# APM32L07x register map
File version: 1.0
CPU: CM0+ r0p0, little endian, MPU, no FPU, 4 interrupt priority bits
Registers are 32-bit, read-write, reset 0x0 unless marked. A register's access mark holds for its fields unless they carry their own. Offsets are from the block's base; [hi:lo] are bit positions.

## USART1 — Universal synchronous asynchronous receiver transmitter
Base 0x40013800
Same registers: USART2 0x40004400, USART4 0x40004C00, USART5 0x40005000
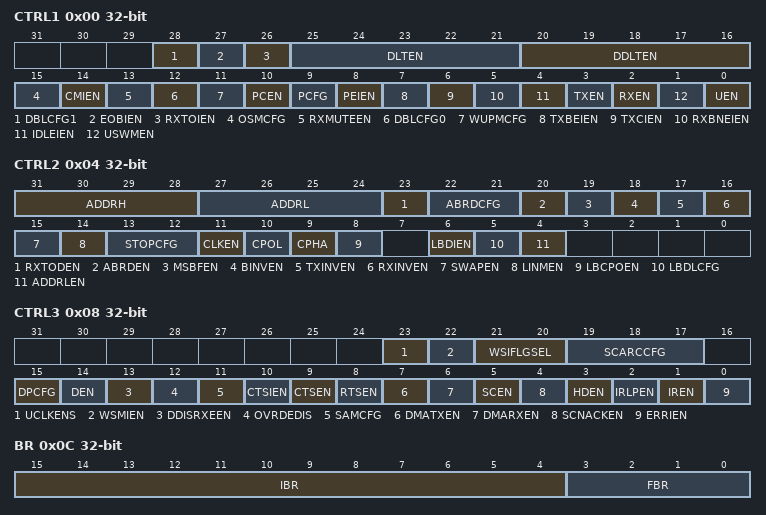
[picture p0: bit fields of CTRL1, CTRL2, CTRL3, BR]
0x00 CTRL1 — Control register 1
  [28] DBLCFG1 — Word length
  [27] EOBIEN — End of Block interrupt enable
  [26] RXTOIEN — Receiver timeout interrupt enable
  [25:21] DLTEN — Driver Enable assertion time
  [20:16] DDLTEN — Driver Enable deassertion time
  [15] OSMCFG — Oversampling mode
  [14] CMIEN — Character match interrupt enable
  [13] RXMUTEEN — Mute mode enable
  [12] DBLCFG0 — Word length
  [11] WUPMCFG — Receiver wakeup method
  [10] PCEN — Parity control enable
  [9] PCFG — Parity selection
  [8] PEIEN — PE interrupt enable
  [7] TXBEIEN — interrupt enable
  [6] TXCIEN — Transmission complete interrupt enable
  [5] RXBNEIEN — RXNE interrupt enable
  [4] IDLEIEN — IDLE interrupt enable
  [3] TXEN — Transmitter enable
  [2] RXEN — Receiver enable
  [1] USWMEN — USART enable in Stop mode
  [0] UEN — USART enable
0x04 CTRL2 — Control register 2
  [31:28] ADDRH — Address of the USART node
  [27:24] ADDRL — Address of the USART node
  [23] RXTODEN — Receiver timeout enable
  [22:21] ABRDCFG — Auto baud rate mode
  [20] ABRDEN — Auto baud rate enable
  [19] MSBFEN — Most significant bit first
  [18] BINVEN — Binary data inversion
  [17] TXINVEN — TX pin active level inversion
  [16] RXINVEN — RX pin active level inversion
  [15] SWAPEN — Swap TX/RX pins
  [14] LINMEN — LIN mode enable
  [13:12] STOPCFG — STOP bits
  [11] CLKEN — Clock enable
  [10] CPOL — Clock polarity
  [9] CPHA — Clock phase
  [8] LBCPOEN — Last bit clock pulse
  [6] LBDIEN — LIN break detection interrupt enable
  [5] LBDLCFG — LIN break detection length
  [4] ADDRLEN — 7-bit Address Detection/4-bit Address Detection
0x08 CTRL3 — Control register 3
  [23] UCLKENS — USART Clock Enable in Stop Mode
  [22] WSMIEN — Wakeup from Stop mode interrupt enable
  [21:20] WSIFLGSEL — Wakeup from Stop mode interrupt flag selection
  [19:17] SCARCCFG — Smartcard auto-retry count
  [15] DPCFG — Driver enable polarity selection
  [14] DEN — Driver enable mode
  [13] DDISRXEEN — DMA Disable on Reception Error
  [12] OVRDEDIS — Overrun Disable
  [11] SAMCFG — One sample bit method enable
  [10] CTSIEN — CTS interrupt enable
  [9] CTSEN — CTS enable
  [8] RTSEN — RTS enable
  [7] DMATXEN — DMA enable transmitter
  [6] DMARXEN — DMA enable receiver
  [5] SCEN — Smartcard mode enable
  [4] SCNACKEN — Smartcard NACK enable
  [3] HDEN — Half-duplex selection
  [2] IRLPEN — IrDA low-power
  [1] IREN — IrDA mode enable
  [0] ERRIEN — Error interrupt enable
0x0C BR — Baud rate register
  [15:4] IBR — mantissa of USARTDIV
  [3:0] FBR — fraction of USARTDIV
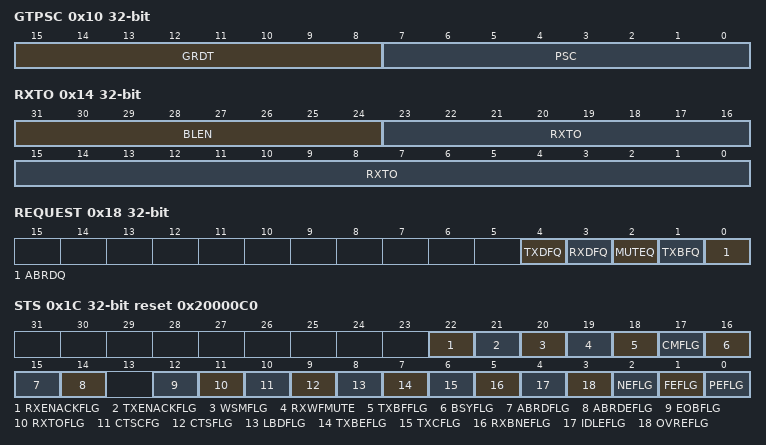
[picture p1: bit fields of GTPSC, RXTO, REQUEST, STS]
0x10 GTPSC — Guard time and prescaler register
  [15:8] GRDT — Guard time value
  [7:0] PSC — Prescaler value
0x14 RXTO — Receiver timeout register
  [31:24] BLEN — Block Length
  [23:0] RXTO — Receiver timeout value
0x18 REQUEST wo
  [4] TXDFQ — Transmit data flush request
  [3] RXDFQ — Receive data flush request
  [2] MUTEQ — Mute mode request
  [1] TXBFQ — Send break request
  [0] ABRDQ — Auto baud rate request
0x1C STS ro reset 0x20000C0 — Interrupt & status register
  [22] RXENACKFLG — Receive enable acknowledge flag
  [21] TXENACKFLG — Transmit enable acknowledge flag
  [20] WSMFLG — Wakeup from Stop mode flag
  [19] RXWFMUTE — Receiver wakeup from Mute mode
  [18] TXBFFLG — Send break flag
  [17] CMFLG — character match flag
  [16] BSYFLG — Busy flag
  [15] ABRDFLG — Auto baud rate flag
  [14] ABRDEFLG — Auto baud rate error
  [12] EOBFLG — End of block flag
  [11] RXTOFLG — Receiver timeout
  [10] CTSCFG — CTS flag
  [9] CTSFLG — CTS interrupt flag
  [8] LBDFLG — LIN break detection flag
  [7] TXBEFLG — Transmit data register empty
  [6] TXCFLG — Transmission complete
  [5] RXBNEFLG — Read data register not empty
  [4] IDLEFLG — Idle line detected
  [3] OVREFLG — Overrun error
  [2] NEFLG — Noise detected flag
  [1] FEFLG — Framing error
  [0] PEFLG — Parity error
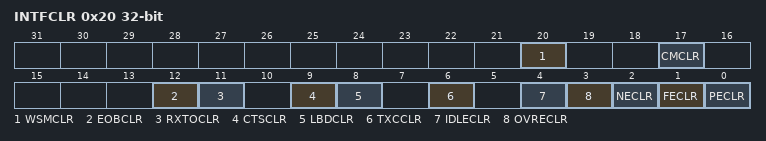
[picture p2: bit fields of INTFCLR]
0x20 INTFCLR — Interrupt flag clear register
  [20] WSMCLR — Wakeup from Stop mode clear flag
  [17] CMCLR — Character match clear flag
  [12] EOBCLR — End of timeout clear flag
  [11] RXTOCLR — Receiver timeout clear flag
  [9] CTSCLR — CTS clear flag
  [8] LBDCLR — LIN break detection clear flag
  [6] TXCCLR — Transmission complete clear flag
  [4] IDLECLR — Idle line detected clear flag
  [3] OVRECLR — Overrun error clear flag
  [2] NECLR — Noise detected clear flag
  [1] FECLR — Framing error clear flag
  [0] PECLR — Parity error clear flag
0x24 RXDATA ro — Receive data register
  [8:0] RXDATA — Receive data value
0x28 TXDATA — Transmit data register
  [8:0] TXDATA — Transmit data value
